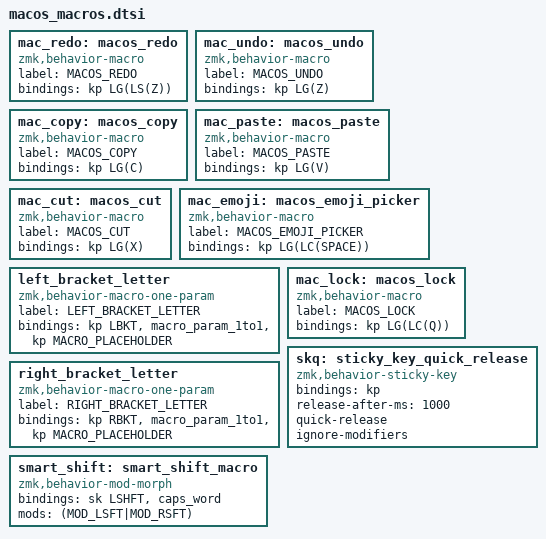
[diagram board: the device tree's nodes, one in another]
mac_redo: macos_redo {
          compatible = "zmk,behavior-macro";
          label = "MACOS_REDO";
          #binding-cells = <0>;
          bindings = <&kp LG(LS(Z))>;
      };

      mac_undo: macos_undo {
          compatible = "zmk,behavior-macro";
          label = "MACOS_UNDO";
          #binding-cells = <0>;
          bindings = <&kp LG(Z)>;
      };

      mac_copy: macos_copy {
          compatible = "zmk,behavior-macro";
          label = "MACOS_COPY";
          #binding-cells = <0>;
          bindings = <&kp LG(C)>;
      };

      mac_paste: macos_paste {
          compatible = "zmk,behavior-macro";
          label = "MACOS_PASTE";
          #binding-cells = <0>;
          bindings = <&kp LG(V)>;
      };

      mac_cut: macos_cut {
          compatible = "zmk,behavior-macro";
          label = "MACOS_CUT";
          #binding-cells = <0>;
          bindings = <&kp LG(X)>;
      };

     mac_emoji: macos_emoji_picker {
          compatible = "zmk,behavior-macro";
          label = "MACOS_EMOJI_PICKER";
          #binding-cells = <0>;
          bindings = <&kp LG(LC(SPACE))>;
      };

    left_bracket_letter: left_bracket_letter {
        compatible = "zmk,behavior-macro-one-param";
        label = "LEFT_BRACKET_LETTER";
        #binding-cells = <1>;
        bindings = <&kp LBKT>, <&macro_param_1to1>, <&kp MACRO_PLACEHOLDER>;
    };

    right_bracket_letter: right_bracket_letter {
        compatible = "zmk,behavior-macro-one-param";
        label = "RIGHT_BRACKET_LETTER";
        #binding-cells = <1>;
        bindings = <&kp RBKT>, <&macro_param_1to1>, <&kp MACRO_PLACEHOLDER>;
    };

    mac_lock: macos_lock {
        compatible = "zmk,behavior-macro";
        label = "MACOS_LOCK";
        #binding-cells = <0>;
        bindings = <&kp LG(LC(Q))>;
    };

    skq: sticky_key_quick_release {
      compatible = "zmk,behavior-sticky-key";
      #binding-cells = <1>;
      bindings = <&kp>;
      release-after-ms = <1000>;
      quick-release;
      ignore-modifiers;
    };

    smart_shift: smart_shift_macro {
      compatible = "zmk,behavior-mod-morph";
      #binding-cells = <0>;
      bindings = <&sk LSHFT>, <&caps_word>;
      mods = <(MOD_LSFT|MOD_RSFT)>;
    };
